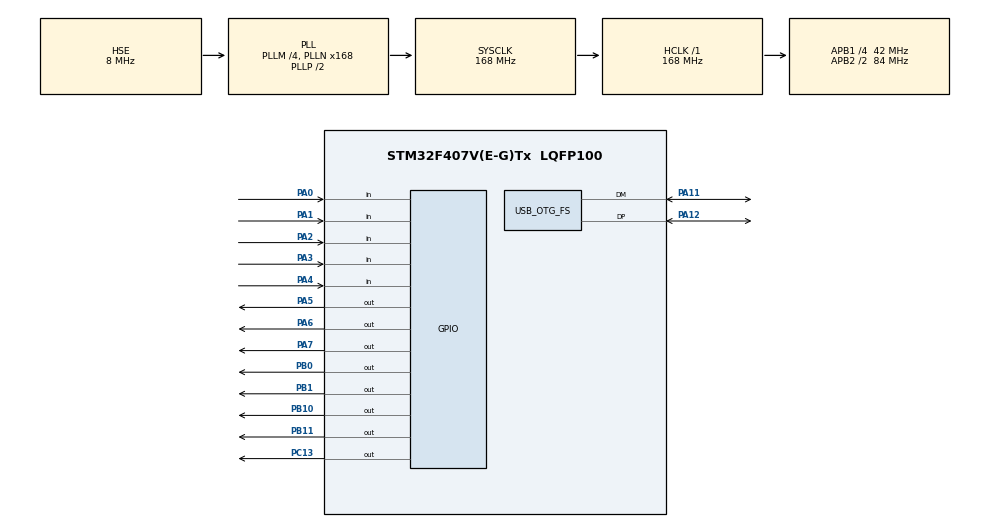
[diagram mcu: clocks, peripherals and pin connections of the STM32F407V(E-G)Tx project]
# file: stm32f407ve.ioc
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Mcu.Family=STM32F4
Mcu.Name=STM32F407V(E-G)Tx
Mcu.Package=LQFP100
NVIC.OTG_FS_IRQn=true\:0\:0\:false\:false\:true\:false\:true
NVIC.PriorityGroup=NVIC_PRIORITYGROUP_4
PA0-WKUP.GPIO_PuPd=GPIO_PULLDOWN
PA0-WKUP.Signal=GPIO_Input
PA1.GPIO_PuPd=GPIO_PULLDOWN
PA1.Signal=GPIO_Input
PA11.Mode=Device_Only
PA11.Signal=USB_OTG_FS_DM
PA12.Mode=Device_Only
PA12.Signal=USB_OTG_FS_DP
PA2.GPIO_PuPd=GPIO_PULLDOWN
PA2.Signal=GPIO_Input
PA3.GPIO_PuPd=GPIO_PULLDOWN
PA3.Signal=GPIO_Input
PA4.GPIO_PuPd=GPIO_PULLDOWN
PA4.Signal=GPIO_Input
PA5.GPIO_PuPd=GPIO_PULLDOWN
PA5.GPIO_Speed=GPIO_SPEED_FREQ_MEDIUM
PA5.Signal=GPIO_Output
PA6.GPIO_PuPd=GPIO_PULLDOWN
PA6.GPIO_Speed=GPIO_SPEED_FREQ_MEDIUM
PA6.Signal=GPIO_Output
PA7.GPIO_PuPd=GPIO_PULLDOWN
PA7.GPIO_Speed=GPIO_SPEED_FREQ_MEDIUM
PA7.Signal=GPIO_Output
PB0.GPIO_PuPd=GPIO_PULLDOWN
PB0.GPIO_Speed=GPIO_SPEED_FREQ_MEDIUM
PB0.Signal=GPIO_Output
PB1.GPIO_PuPd=GPIO_PULLDOWN
PB1.GPIO_Speed=GPIO_SPEED_FREQ_MEDIUM
PB1.Signal=GPIO_Output
PB10.GPIO_PuPd=GPIO_PULLDOWN
PB10.GPIO_Speed=GPIO_SPEED_FREQ_MEDIUM
PB10.Signal=GPIO_Output
PB11.GPIO_PuPd=GPIO_PULLDOWN
PB11.GPIO_Speed=GPIO_SPEED_FREQ_MEDIUM
PB11.Signal=GPIO_Output
PC13-ANTI_TAMP.GPIO_PuPd=GPIO_PULLDOWN
PC13-ANTI_TAMP.Signal=GPIO_Output
PH0-OSC_IN.Mode=HSE-External-Oscillator
PH0-OSC_IN.Signal=RCC_OSC_IN
PH1-OSC_OUT.Mode=HSE-External-Oscillator
PH1-OSC_OUT.Signal=RCC_OSC_OUT
ProjectManager.HeapSize=0x200
ProjectManager.StackSize=0x400
ProjectManager.TargetToolchain=SW4STM32
RCC.48MHZClocksFreq_Value=48000000
RCC.AHBFreq_Value=168000000
RCC.APB1CLKDivider=RCC_HCLK_DIV4
RCC.APB1Freq_Value=42000000
RCC.APB1TimFreq_Value=84000000
RCC.APB2CLKDivider=RCC_HCLK_DIV2
RCC.APB2Freq_Value=84000000
RCC.APB2TimFreq_Value=168000000
RCC.CortexFreq_Value=168000000
RCC.HCLKFreq_Value=168000000
RCC.HSE_VALUE=8000000
RCC.HSI_VALUE=16000000
RCC.LSE_VALUE=32768
RCC.PLLM=4
RCC.PLLN=168
RCC.PLLQ=7
RCC.SYSCLKFreq_VALUE=168000000
RCC.SYSCLKSource=RCC_SYSCLKSOURCE_PLLCLK
RCC.VCOOutputFreq_Value=336000000
USB_OTG_FS.VirtualMode=Device_Only
board=custom

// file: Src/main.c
/* USER CODE BEGIN Header */
/**
 ******************************************************************************
 * @file           : main.c
 * @brief          : Main program body
 ******************************************************************************
 * @attention
 *
 * <h2><center>&copy; Copyright (c) 2020 STMicroelectronics.
 * All rights reserved.</center></h2>
 *
 * This software component is licensed by ST under BSD 3-Clause license,
 * the "License"; You may not use this file except in compliance with the
 * License. You may obtain a copy of the License at:
 *                        opensource.org/licenses/BSD-3-Clause
 *
 ******************************************************************************
 */
/* USER CODE END Header */

#include "main.h"

/* USER CODE BEGIN Includes */
#include "startup.h"
#include "Sound/usb_device.h"
#include "Sound/usbd_midi_if.h"
/* USER CODE END Includes */

PCD_HandleTypeDef hpcd_USB_OTG_FS;

void SystemClock_Config(void);
static void MX_GPIO_Init(void);
static void MX_USB_OTG_FS_PCD_Init(void);

int main(void)
{

  /* MCU Configuration--------------------------------------------------------*/

  /* Reset of all peripherals, Initializes the Flash interface and the Systick. */
  HAL_Init();

  /* Configure the system clock */
  SystemClock_Config();

  /* USER CODE BEGIN SysInit */
	initialize();
  /* USER CODE END SysInit */

  /* Initialize all configured peripherals */
  MX_GPIO_Init();
  MX_USB_OTG_FS_PCD_Init();
  /* USER CODE BEGIN 2 */

	// USB MIDI
	HAL_NVIC_SetPriority(OTG_FS_IRQn, 2, 0);
	HAL_NVIC_EnableIRQ(OTG_FS_IRQn);
	MX_USB_DEVICE_Init();
  /* USER CODE END 2 */

  /* Infinite loop */
  /* USER CODE BEGIN WHILE */
	while (1) {
		loop();
    /* USER CODE END WHILE */

	}
}

void SystemClock_Config(void)
{
  RCC_OscInitTypeDef RCC_OscInitStruct = {0};
  RCC_ClkInitTypeDef RCC_ClkInitStruct = {0};

  /** Configure the main internal regulator output voltage
  */
  __HAL_RCC_PWR_CLK_ENABLE();
  __HAL_PWR_VOLTAGESCALING_CONFIG(PWR_REGULATOR_VOLTAGE_SCALE1);
  /** Initializes the CPU, AHB and APB busses clocks
  */
  RCC_OscInitStruct.OscillatorType = RCC_OSCILLATORTYPE_HSE;
  RCC_OscInitStruct.HSEState = RCC_HSE_ON;
  RCC_OscInitStruct.PLL.PLLState = RCC_PLL_ON;
  RCC_OscInitStruct.PLL.PLLSource = RCC_PLLSOURCE_HSE;
  RCC_OscInitStruct.PLL.PLLM = 4;
  RCC_OscInitStruct.PLL.PLLN = 168;
  RCC_OscInitStruct.PLL.PLLP = RCC_PLLP_DIV2;
  RCC_OscInitStruct.PLL.PLLQ = 7;
  if (HAL_RCC_OscConfig(&RCC_OscInitStruct) != HAL_OK)
  {
    Error_Handler();
  }
  /** Initializes the CPU, AHB and APB busses clocks
  */
  RCC_ClkInitStruct.ClockType = RCC_CLOCKTYPE_HCLK|RCC_CLOCKTYPE_SYSCLK
                              |RCC_CLOCKTYPE_PCLK1|RCC_CLOCKTYPE_PCLK2;
  RCC_ClkInitStruct.SYSCLKSource = RCC_SYSCLKSOURCE_PLLCLK;
  RCC_ClkInitStruct.AHBCLKDivider = RCC_SYSCLK_DIV1;
  RCC_ClkInitStruct.APB1CLKDivider = RCC_HCLK_DIV4;
  RCC_ClkInitStruct.APB2CLKDivider = RCC_HCLK_DIV2;

  if (HAL_RCC_ClockConfig(&RCC_ClkInitStruct, FLASH_LATENCY_5) != HAL_OK)
  {
    Error_Handler();
  }
}

static void MX_USB_OTG_FS_PCD_Init(void)
{

  hpcd_USB_OTG_FS.Instance = USB_OTG_FS;
  hpcd_USB_OTG_FS.Init.dev_endpoints = 4;
  hpcd_USB_OTG_FS.Init.speed = PCD_SPEED_FULL;
  hpcd_USB_OTG_FS.Init.dma_enable = DISABLE;
  hpcd_USB_OTG_FS.Init.phy_itface = PCD_PHY_EMBEDDED;
  hpcd_USB_OTG_FS.Init.Sof_enable = DISABLE;
  hpcd_USB_OTG_FS.Init.low_power_enable = DISABLE;
  hpcd_USB_OTG_FS.Init.lpm_enable = DISABLE;
  hpcd_USB_OTG_FS.Init.vbus_sensing_enable = DISABLE;
  hpcd_USB_OTG_FS.Init.use_dedicated_ep1 = DISABLE;
  if (HAL_PCD_Init(&hpcd_USB_OTG_FS) != HAL_OK)
  {
    Error_Handler();
  }

}

static void MX_GPIO_Init(void)
{
  GPIO_InitTypeDef GPIO_InitStruct = {0};

  /* GPIO Ports Clock Enable */
  __HAL_RCC_GPIOC_CLK_ENABLE();
  __HAL_RCC_GPIOH_CLK_ENABLE();
  __HAL_RCC_GPIOA_CLK_ENABLE();
  __HAL_RCC_GPIOB_CLK_ENABLE();

  /*Configure GPIO pin Output Level */
  HAL_GPIO_WritePin(GPIOC, GPIO_PIN_13, GPIO_PIN_RESET);

  /*Configure GPIO pin Output Level */
  HAL_GPIO_WritePin(GPIOA, GPIO_PIN_5|GPIO_PIN_6|GPIO_PIN_7, GPIO_PIN_RESET);

  /*Configure GPIO pin Output Level */
  HAL_GPIO_WritePin(GPIOB, GPIO_PIN_0|GPIO_PIN_1|GPIO_PIN_10|GPIO_PIN_11, GPIO_PIN_RESET);

  /*Configure GPIO pin : PC13 */
  GPIO_InitStruct.Pin = GPIO_PIN_13;
  GPIO_InitStruct.Mode = GPIO_MODE_OUTPUT_PP;
  GPIO_InitStruct.Pull = GPIO_PULLDOWN;
  GPIO_InitStruct.Speed = GPIO_SPEED_FREQ_LOW;
  HAL_GPIO_Init(GPIOC, &GPIO_InitStruct);

  /*Configure GPIO pins : PA0 PA1 PA2 PA3
                           PA4 */
  GPIO_InitStruct.Pin = GPIO_PIN_0|GPIO_PIN_1|GPIO_PIN_2|GPIO_PIN_3
                          |GPIO_PIN_4;
  GPIO_InitStruct.Mode = GPIO_MODE_INPUT;
  GPIO_InitStruct.Pull = GPIO_PULLDOWN;
  HAL_GPIO_Init(GPIOA, &GPIO_InitStruct);

  /*Configure GPIO pins : PA5 PA6 PA7 */
  GPIO_InitStruct.Pin = GPIO_PIN_5|GPIO_PIN_6|GPIO_PIN_7;
  GPIO_InitStruct.Mode = GPIO_MODE_OUTPUT_PP;
  GPIO_InitStruct.Pull = GPIO_PULLDOWN;
  GPIO_InitStruct.Speed = GPIO_SPEED_FREQ_MEDIUM;
  HAL_GPIO_Init(GPIOA, &GPIO_InitStruct);

  /*Configure GPIO pins : PB0 PB1 PB10 PB11 */
  GPIO_InitStruct.Pin = GPIO_PIN_0|GPIO_PIN_1|GPIO_PIN_10|GPIO_PIN_11;
  GPIO_InitStruct.Mode = GPIO_MODE_OUTPUT_PP;
  GPIO_InitStruct.Pull = GPIO_PULLDOWN;
  GPIO_InitStruct.Speed = GPIO_SPEED_FREQ_MEDIUM;
  HAL_GPIO_Init(GPIOB, &GPIO_InitStruct);

}

void Error_Handler(void)
{
}

/************************ (C) COPYRIGHT STMicroelectronics *****END OF FILE****/
